# NUC505_v1 register map
File version: 1.0
Registers are 32-bit, read-write, reset 0x0 unless marked. A register's access mark holds for its fields unless they carry their own. Offsets are from the block's base; [hi:lo] are bit positions; {n}, {i} and the like mark numbered series; 'fields as' and 'values as' point back to an identical list.

## I2C0 — I2C Register Map
Base 0x400E4000
Same registers: I2C1 0x400E5000
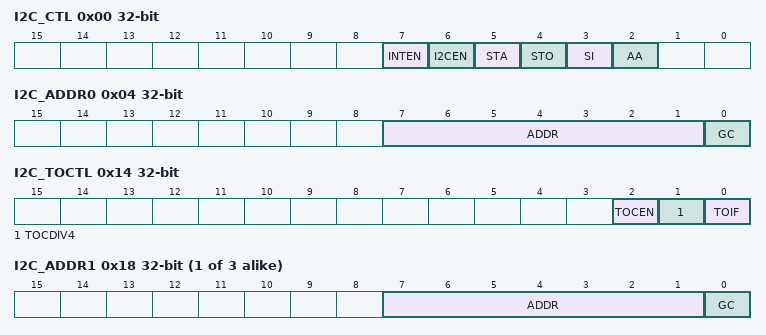
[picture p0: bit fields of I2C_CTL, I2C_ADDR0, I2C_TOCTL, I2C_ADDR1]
0x00 I2C_CTL — I2C Control Register
  [7] INTEN — I2C Interrupt Enable Control
    0=I2C interrupt Disabled; 1=I2C interrupt Enabled
  [6] I2CEN — I2C Controller Enable Control
    0=Disabled; 1=Enabled
  [5] STA — I2C START Control. Setting STA to logic 1 to enter Master mode, the I2C hardware sends a START or repeat START condition to bus when the bus is free.
  [4] STO — I2C STOP Control. In Master mode, setting STO to transmit a STOP condition to bus then I2C hardware will check the bus condition if a STOP condition is detected this bit will be cleared by hardware automatically. In Slave mode, setting STO resets I2C hardware to the defined "not addressed" Slave mode. This means it is NO LONGER in the slave receiver mode to receive data from the master transmit device.
  [3] SI — I2C Interrupt Flag. When a new I2C state is present in the I2C_STATUS register, the SI flag is set by hardware, and if bit INTEN (I2C_CTL [7]) is set, the I2C interrupt is requested. SI must be cleared by software. Clear SI by writing 1 to this bit.
  [2] AA — Assert Acknowledge Control
0x04 I2C_ADDR0 — I2C Slave Address Register0
  [7:1] ADDR — I2C Address Bits. The content of this register is irrelevant when I2C is in Master mode. In Slave mode, the seven most significant bits must be loaded with the chip's own address. The I2C hardware will react if either of the address is matched.
  [0] GC — General Call Function
    0=General Call Function Disabled; 1=General Call Function Enabled
0x08 I2C_DAT — I2C Data Register
  [7:0] DAT — I2C Data Bits. Bit [7:0] is located with the 8-bit transferred data of I2C serial port.
0x0C I2C_STATUS ro reset 0xF8
  [7:0] STATUS — I2C Status Bits. The status register of I2C: The three least significant bits are always 0. The five most significant bits contain the status code. Refer to section 6.11.6.4 for detail description.
0x10 I2C_CLKDIV — I2C Clock Divided Register
  [7:0] DIVIDER — I2C Clock Divided Bits. The minimum value of DIVIDER is 4.
0x14 I2C_TOCTL — I2C Time-out Control Register
  [2] TOCEN — Time-out Counter Enable Control. Note: When Enabled, the 14-bit time-out counter will start counting when SI (I2C_CTL[3]) is cleared. Setting flag SI to high will reset counter and re-start up counting after SI is cleared.
    0=Disabled; 1=Enabled
  [1] TOCDIV4 — Time-out Counter Input Clock Divided by 4. Note When Enabled, The time-out period is extend 4 times.
    0=Disabled; 1=Enabled
  [0] TOIF — Time-out Flag. This bit is set by H/W when I2C time-out happened and it can interrupt CPU if I2C interrupt enable bit (INTEN (I2C_CTL[7])) is set to 1. Write 1 to clear this bit.
{0x14+4i} I2C_ADDR{i} (i=1..3) — I2C Slave Address Register{i}
  fields as I2C_ADDR0
{0x24+4i} I2C_ADDRMSK{i} (i=0..3) — I2C Slave Address Mask Register{i}
  [7:1] ADDRMSK — I2C Address Mask Bits. I2C bus controllers support multiple address recognition with four address mask register. When the bit in the address mask register is set to one, it means the received corresponding address bit is don't-care. If the bit is set to zero, that means the received corresponding register bit should be exact the same as address register.
    0=Mask Disabled (the received corresponding register bit should be exact the same as address register.); 1=Mask Enabled (the received corresponding address bit is don't care.)
0x3C I2C_WKCTL — I2C Wake-up Control Register
  [0] WKEN — I2C Wake-up Enable Control
    0=I2C wake-up function Disabled; 1=I2C wake-up function Enabled
0x40 I2C_WKSTS — I2C Wake-up Status Register
  [0] WKIF — I2C Wake-up Flag. Note: Software can write 1 to clear this bit.
    0=No wake up occurred; 1=Wake up from Power-down mode

## ADC — ADC Register Map
Base 0x400E2000
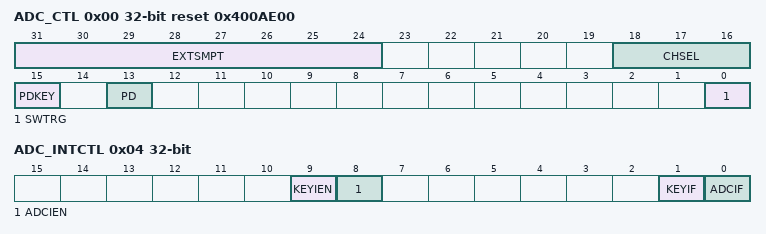
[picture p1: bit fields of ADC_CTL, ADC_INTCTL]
0x00 ADC_CTL reset 0x400AE00 — ADC Control Register
  [31:24] EXTSMPT — ADC Extend Sampling Time. When A/D converting at high conversion rate, the sampling time of analog input voltage may not enough if the input channel loading is heavy, software can extend A/D sampling time after trigger source is coming to get enough sampling time. Note: The unit is ADC clock.
  [18:16] CHSEL — Analog Input Selection Signals. Note1: ADC_CH0 is used for battery voltage detection. It includes an inherent resistor divider and a switch. Note2: User needs to pay attention to electric leakage with ADC_CH0 because the default CHSEL is selected to ADC_CH0, and ADC_CH0 has an internal resistor divider. If ADC_CH0 is connected to battery, there is a leakage path. Therefore, user can change CHSEL to other channel to cut off this path, when finishing battery detection.
    {v}=ADC_CH{v} (v=0..7)
  [15] PDKEY — Power Down Keypad Detection
    0=Power down keypad detection Disabled; 1=Power down keypad detection Enabled
  [13] PD — Power Down ADC. Note1: ADC power must be enabled before a trigger to get the data. Note2: It needs 100ms to wait analog block stable when setting PD from 1 to 0.
    0=ADC is in normal state; 1=ADC is in power down state
  [0] SWTRG — A/D Conversion Start. A trigger to start one A/D conversion process. Note: This bit will be cleared to '0' automatically.
    0=A/D conversion enters idle state; 1=Start conversion
0x04 ADC_INTCTL — ADC Interrupt State
  [9] KEYIEN — Keypad Interrupt Enable Control
    0=Keypad down interrupt Disabled; 1=Keypad down interrupt Enabled
  [8] ADCIEN — ADC Interrupt Enable Control
    0=ADC conversion done interrupt Disabled; 1=ADC conversion done interrupt Enabled
  [1] KEYIF — Keypad Interrupt Flag. In the process of checking keypad, the KEYIF shows the state. ADC_CH2 is used for keypad. When ADC_CH2 is not equal to AVDDADC, the interrupt flag will be raised.
    0=Keypad is not pressing state; 1=keypad is pressing state
  [0] ADCIF — ADC Conversion Done Interrupt Flag. When finishing the sample process, the ADCIF bit will be set. If the ADCIEN is set, the interrupt will be transferred to NVIC.
    0=ADC conversion done flag is not set; 1=ADC conversion done flag is set
0x08 ADC_DAT ro — ADC Data Register
  [11:0] RESULT — A/D Conversion Result. This field contains conversion result of ADC. When A/D conversion done, 12-bit ADC conversion result with unsigned format will be filled in RESULT[11:0].
